# ESP32-C2 register map
Vendor: ESPRESSIF SYSTEMS (SHANGHAI) CO., LTD.; Series: ESP32-C2; File version: 4
32-bit RISC-V MCU
CPU: RV32IMC r0p0, little endian, no MPU, no FPU, 4 interrupt priority bits
Address unit: 32 bits
Registers are 32-bit, read-write, reset 0x0 unless marked. A register's access mark holds for its fields unless they carry their own. Offsets are from the block's base; lines under a group give offsets from that group; [hi:lo] are bit positions; {n}, {i} and the like mark numbered series; 'fields as' and 'values as' point back to an identical list; <NAME> marks a mode.

## Memory map
0x60000000 UART0 size 0x84 — UART (Universal Asynchronous Receiver-Transmitter) Controller
0x60002000 SPI1 size 0xA8 — SPI (Serial Peripheral Interface) Controller
0x60003000 SPI0 size 0x48 — SPI (Serial Peripheral Interface) Controller
0x60004000 GPIO size 0x314 — General Purpose Input/Output
0x60008000 RTC_CNTL size 0x114 — Real Time Controller
0x60008800 EFUSE size 0xC0 — eFuse Controller
0x60009000 IO_MUX size 0x5C — Input/Output Multiplexer
0x60010000 UART1 size 0x84 — UART (Universal Asynchronous Receiver-Transmitter) Controller
0x60013000 I2C0 size 0x88 — I2C (Inter-Integrated Circuit) Controller
0x60019000 LEDC size 0xB0 — LED PWM (Pulse Width Modulation) Controller
0x6001F000 TIMG0 size 0x68 — Timer Group
0x60023000 SYSTIMER size 0x78 — System Timer
0x60024000 SPI2 size 0x98 — SPI (Serial Peripheral Interface) Controller
0x60026000 APB_CTRL size 0xA0 — Advanced Peripheral Bus Controller
0x60026000 RNG size 0x4 — Hardware random number generator
0x6003B000 SHA size 0xB0 — SHA (Secure Hash Algorithm) Accelerator
0x6003E000 ECC size 0x18 — ECC (ECC Hardware Accelerator)
0x6003F000 DMA size 0x84 — DMA (Direct Memory Access) Controller
0x60040000 APB_SARADC size 0x68 — Successive Approximation Register Analog to Digital Converter
0x600C0000 SYSTEM size 0xA0
0x600C1000 SENSITIVE size 0x48
0x600C2000 INTERRUPT_CORE0 size 0x150 — Interrupt Core
0x600C4000 EXTMEM size 0x94 — External Memory
0x600CC000 XTS_AES size 0x30 — XTS-AES-128 Flash Encryption
0x600CE000 ASSIST_DEBUG size 0x38 — Debug Assist

## Interrupts
11 I2C_MST (I2C0)
12 APB_CTRL
13 GPIO
14 GPIO_NMI (GPIO)
15 SPI_INTR_1 (SPI2)
16 SPI_INTR_2 (SPI2)
17 UART0
18 UART1
19 LEDC
20 EFUSE
21 RTC_CORE (RTC_CNTL)
22 I2C_EXT0 (I2C0)
23 TG0_T0_LEVEL (TIMG0)
24 TG0_WDT_LEVEL (TIMG0)
26 SYSTIMER_TARGET0 (SYSTIMER)
27 SYSTIMER_TARGET1 (SYSTIMER)
28 SYSTIMER_TARGET2 (SYSTIMER)
29 SPI_MEM_REJECT_CACHE (SPI0)
32 APB_ADC (APB_SARADC)
33 DMA_CH0 (DMA)
34 SHA

## ASSIST_DEBUG — Debug Assist
Base 0x600CE000
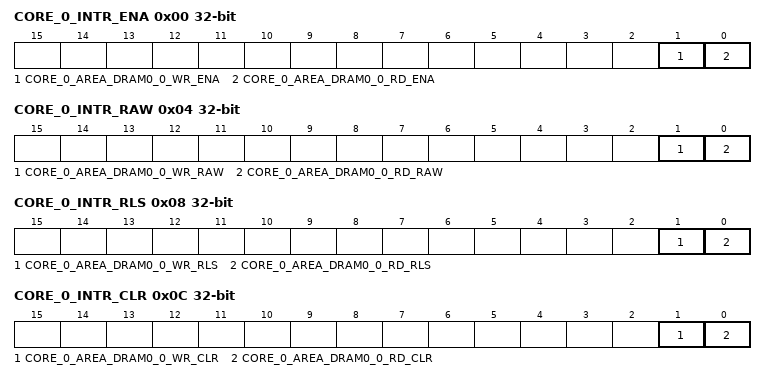
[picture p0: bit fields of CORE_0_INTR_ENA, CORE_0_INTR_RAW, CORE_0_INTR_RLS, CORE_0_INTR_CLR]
0x00 CORE_0_INTR_ENA — core0 monitor enable configuration register
  [1] CORE_0_AREA_DRAM0_0_WR_ENA — enbale sp overflow monitor
  [0] CORE_0_AREA_DRAM0_0_RD_ENA — enbale sp underlow monitor
0x04 CORE_0_INTR_RAW ro — core0 monitor interrupt status register
  [1] CORE_0_AREA_DRAM0_0_WR_RAW — sp overflow monitor interupt status register
  [0] CORE_0_AREA_DRAM0_0_RD_RAW — sp underlow monitor interrupt status register
0x08 CORE_0_INTR_RLS — core0 monitor interrupt enable register
  [1] CORE_0_AREA_DRAM0_0_WR_RLS — enbale sp overflow monitor interrupt
  [0] CORE_0_AREA_DRAM0_0_RD_RLS — enbale sp underlow monitor interrupt
0x0C CORE_0_INTR_CLR wo — core0 monitor interrupt clr register
  [1] CORE_0_AREA_DRAM0_0_WR_CLR — clr sp overflow monitor interrupt
  [0] CORE_0_AREA_DRAM0_0_RD_CLR — clr sp underlow monitor interrupt
0x10 CORE_0_SP_MIN — stack min value
  [31:0] CORE_0_SP_MIN — core0 sp region configuration regsiter
0x14 CORE_0_SP_MAX reset 0xFFFFFFFF — stack max value
  [31:0] CORE_0_SP_MAX — core0 sp pc status register
0x18 CORE_0_SP_PC ro — stack monitor pc status register
  [31:0] CORE_0_SP_PC — This regsiter stores the PC when trigger stack monitor.
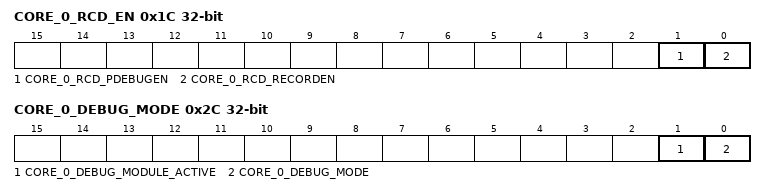
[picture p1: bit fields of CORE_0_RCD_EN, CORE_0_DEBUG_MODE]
0x1C CORE_0_RCD_EN — record enable configuration register
  [1] CORE_0_RCD_PDEBUGEN — Set 1 to enable cpu pdebug function, must set this bit can get cpu PC
  [0] CORE_0_RCD_RECORDEN — Set 1 to enable record PC
0x20 CORE_0_RCD_PDEBUGPC ro — record status regsiter
  [31:0] CORE_0_RCD_PDEBUGPC — recorded PC
0x24 CORE_0_RCD_PDEBUGSP ro — record status regsiter
  [31:0] CORE_0_RCD_PDEBUGSP — recorded sp
0x28 CORE_0_LASTPC_BEFORE_EXCEPTION ro — cpu status register
  [31:0] CORE_0_LASTPC_BEFORE_EXC — cpu's lastpc before exception
0x2C CORE_0_DEBUG_MODE ro — cpu status register
  [1] CORE_0_DEBUG_MODULE_ACTIVE — cpu debug_module active status
  [0] CORE_0_DEBUG_MODE — cpu debug mode status, 1 means cpu enter debug mode.
0x30 CLOCK_GATE reset 0x1
  [0] CLK_EN
0x1FC DATE reset 0x2106020 — version register
  [27:0] DATE

## Licence text in the file
Copyright 2022 Espressif Systems (Shanghai) PTE LTD Licensed under the Apache License, Version 2.0 (the "License"); you may not use this file except in compliance with the License. You may obtain a copy of the License at http://www.apache.org/licenses/LICENSE-2.0 Unless required by applicable law or agreed to in writing, software distributed under the License is distributed on an "AS IS" BASIS, WITHOUT WARRANTIES OR CONDITIONS OF ANY KIND, either express or implied. See the License for the specific language governing permissions and limitations under the License.
